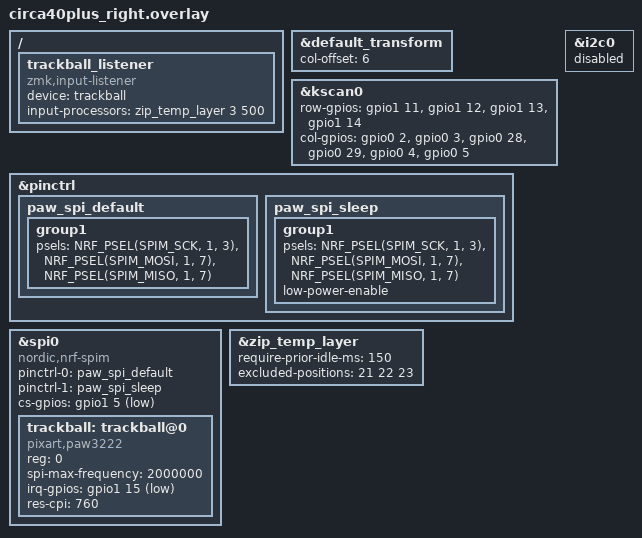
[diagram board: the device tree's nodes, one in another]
#include "circa40plus.dtsi"
#include <zephyr/dt-bindings/pinctrl/nrf-pinctrl.h>
#include <input/processors.dtsi>

&default_transform { col-offset = <6>; };

&kscan0 {
    // U1 pads 7..10: Row0..3_R.
    row-gpios = <&gpio1 11 (GPIO_ACTIVE_HIGH | GPIO_PULL_DOWN)>,
                <&gpio1 12 (GPIO_ACTIVE_HIGH | GPIO_PULL_DOWN)>,
                <&gpio1 13 (GPIO_ACTIVE_HIGH | GPIO_PULL_DOWN)>,
                <&gpio1 14 (GPIO_ACTIVE_HIGH | GPIO_PULL_DOWN)>;
    // U1 pads 1..6: Col0..5_R.
    col-gpios = <&gpio0 2 GPIO_ACTIVE_HIGH>,
                <&gpio0 3 GPIO_ACTIVE_HIGH>,
                <&gpio0 28 GPIO_ACTIVE_HIGH>,
                <&gpio0 29 GPIO_ACTIVE_HIGH>,
                <&gpio0 4 GPIO_ACTIVE_HIGH>,
                <&gpio0 5 GPIO_ACTIVE_HIGH>;
};

// SPI0 and I2C0 share the same hardware instance on nRF52840.
&i2c0 { status = "disabled"; };

&pinctrl {
    paw_spi_default: paw_spi_default {
        group1 {
            psels = <NRF_PSEL(SPIM_SCK, 1, 3)>,
                    <NRF_PSEL(SPIM_MOSI, 1, 7)>,
                    <NRF_PSEL(SPIM_MISO, 1, 7)>;
        };
    };
    paw_spi_sleep: paw_spi_sleep {
        group1 {
            psels = <NRF_PSEL(SPIM_SCK, 1, 3)>,
                    <NRF_PSEL(SPIM_MOSI, 1, 7)>,
                    <NRF_PSEL(SPIM_MISO, 1, 7)>;
            low-power-enable;
        };
    };
};

&spi0 {
    compatible = "nordic,nrf-spim";
    status = "okay";
    pinctrl-0 = <&paw_spi_default>;
    pinctrl-1 = <&paw_spi_sleep>;
    pinctrl-names = "default", "sleep";
    cs-gpios = <&gpio1 5 GPIO_ACTIVE_LOW>;

    trackball: trackball@0 {
        compatible = "pixart,paw3222";
        status = "okay";
        reg = <0>;
        spi-max-frequency = <2000000>;
        irq-gpios = <&gpio1 15 (GPIO_ACTIVE_LOW | GPIO_PULL_UP)>;
        res-cpi = <760>;
    };
};

/* デフォルトの zip_temp_layer ノードを拡張:
 * - require-prior-idle-ms: 直前のキー入力から 150ms 以上経っていないと
 *   AML を発動させない（タイプ中に手のひらがボールへ軽く触れた程度の誤発動を防ぐ）。
 * - excluded-positions: mouse レイヤー (circa40plus.keymap の4番目 = レイヤー3) の
 *   LCLK(21) / MCLK(22) / RCLK(23) の位置。この3キー以外が押されたらタイムアウト前でも
 *   即座にAML終了、この3キー（クリック自身）を押してもAMLは維持される。
 *   位置番号は circa40plus.dtsi の matrix-transform 順（0始まり、行ごとに連番）。 */
&zip_temp_layer {
    require-prior-idle-ms = <150>;
    excluded-positions = <21 22 23>;
};

/ {
    trackball_listener: trackball_listener {
        compatible = "zmk,input-listener";
        device = <&trackball>;

        /* Auto Mouse Layer: ボールが動いた瞬間に mouse レイヤー(3, LCLK/MCLK/RCLK)を
         * 自動オンにし、動きが無くなってから 500ms 後に自動オフに戻す。
         * ベースの LCLK/RCLK・systemレイヤーのMCLKはそのまま残しているので、
         * 従来通りの手動アクセスと併用可能。タイミングが合わなければ
         * 500 の数値だけ調整する（大きいほど戻るまで長く留まる）。 */
        input-processors = <&zip_temp_layer 3 500>;
    };
};
